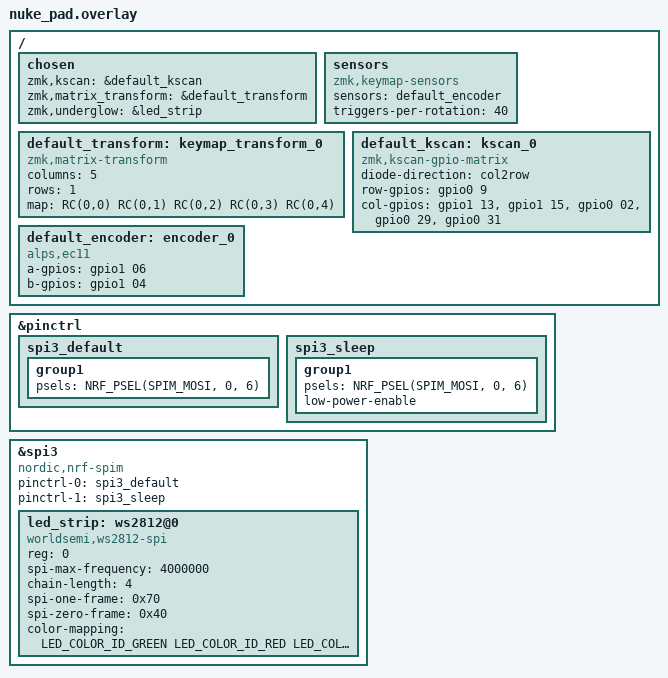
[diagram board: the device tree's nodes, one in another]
/*
 * Copyright (c) 2020 The ZMK Contributors
 *
 * SPDX-License-Identifier: MIT
 */

#include <dt-bindings/zmk/matrix_transform.h>
#include <dt-bindings/led/led.h>

&pinctrl {
    spi3_default: spi3_default {
        group1 {
            psels = <NRF_PSEL(SPIM_MOSI, 0, 6)>;
        };
    };

    spi3_sleep: spi3_sleep {
        group1 {
            psels = <NRF_PSEL(SPIM_MOSI, 0, 6)>;
            low-power-enable;
        };
    };
};

&spi3 {
  compatible = "nordic,nrf-spim";
  status = "okay";

  pinctrl-0 = <&spi3_default>;
  pinctrl-1 = <&spi3_sleep>;
  pinctrl-names = "default", "sleep";

  led_strip: ws2812@0 {
    compatible = "worldsemi,ws2812-spi";

    /* SPI */
    reg = <0>; /* ignored, but necessary for SPI bindings */
    spi-max-frequency = <4000000>;

    /* WS2812 */
    chain-length = <4>; /* number of LEDs */
    spi-one-frame = <0x70>;
    spi-zero-frame = <0x40>;
    color-mapping = <LED_COLOR_ID_GREEN
                          LED_COLOR_ID_RED
                          LED_COLOR_ID_BLUE>;
  };
};

/ {
    chosen {
        zmk,kscan = &default_kscan;
        zmk,matrix_transform = &default_transform;
        zmk,underglow = &led_strip;
    };

    sensors {
        compatible = "zmk,keymap-sensors";
        sensors = <&default_encoder>;
        triggers-per-rotation = <40>;
    };

    default_transform: keymap_transform_0 {
        compatible = "zmk,matrix-transform";
        columns = <5>;
        rows = <1>;
        map = <
            RC(0,0) RC(0,1) RC(0,2) RC(0,3) RC(0,4)
        >;
    };

    default_kscan: kscan_0 {
        compatible = "zmk,kscan-gpio-matrix";
        diode-direction = "col2row";

        row-gpios = <&gpio0 9 (GPIO_ACTIVE_HIGH | GPIO_PULL_DOWN)>;

        col-gpios
            = <&gpio1 13 GPIO_ACTIVE_HIGH>
            , <&gpio1 15 GPIO_ACTIVE_HIGH>
            , <&gpio0 02 GPIO_ACTIVE_HIGH>
            , <&gpio0 29 GPIO_ACTIVE_HIGH>
            , <&gpio0 31 GPIO_ACTIVE_HIGH>
            ;
    };

    default_encoder: encoder_0 {
        compatible = "alps,ec11";
        a-gpios = <&gpio1 06 (GPIO_ACTIVE_HIGH | GPIO_PULL_UP)>;
        b-gpios = <&gpio1 04 (GPIO_ACTIVE_HIGH | GPIO_PULL_UP)>;
        status = "okay";
    };
};
